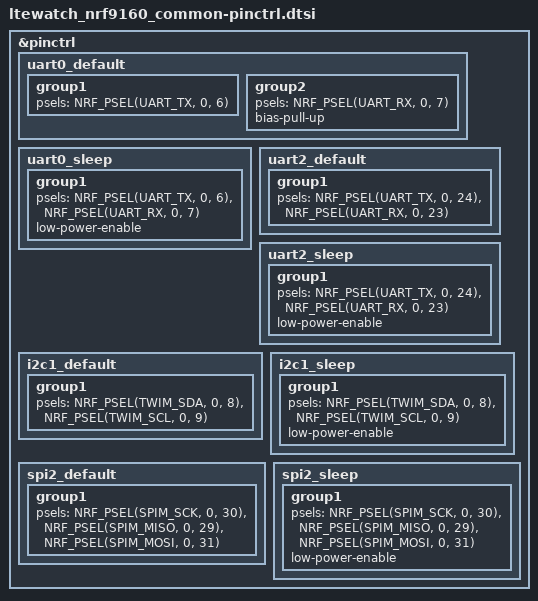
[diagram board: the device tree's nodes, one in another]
/*
 * Copyright (c) 2022 Nordic Semiconductor
 * SPDX-License-Identifier: Apache-2.0
 */

&pinctrl {
	uart0_default: uart0_default {
		group1 {
			psels = <NRF_PSEL(UART_TX, 0, 6)>;
		};
		group2 {
			psels = <NRF_PSEL(UART_RX, 0, 7)>;
			bias-pull-up;
		};
	};

	uart0_sleep: uart0_sleep {
		group1 {
			psels = <NRF_PSEL(UART_TX, 0, 6)>,
				<NRF_PSEL(UART_RX, 0, 7)>;
			low-power-enable;
		};
	};

	uart2_default: uart2_default {
		group1 {
			psels = <NRF_PSEL(UART_TX, 0, 24)>,
				<NRF_PSEL(UART_RX, 0, 23)>;
		};
	};
	
	uart2_sleep: uart2_sleep {
		group1 {
			psels = <NRF_PSEL(UART_TX, 0, 24)>,
				<NRF_PSEL(UART_RX, 0, 23)>;
			low-power-enable;
		};
	};

	i2c1_default: i2c1_default {
		group1 {
			psels = <NRF_PSEL(TWIM_SDA, 0, 8)>,
				<NRF_PSEL(TWIM_SCL, 0, 9)>;
		};
	};

	i2c1_sleep: i2c1_sleep {
		group1 {
			psels = <NRF_PSEL(TWIM_SDA, 0, 8)>,
				<NRF_PSEL(TWIM_SCL, 0, 9)>;
			low-power-enable;
		};
	};

	spi2_default: spi2_default {
		group1 {
			psels = <NRF_PSEL(SPIM_SCK, 0, 30)>,
					<NRF_PSEL(SPIM_MISO, 0, 29)>,
					<NRF_PSEL(SPIM_MOSI, 0, 31)>;
		};
	};

	spi2_sleep: spi2_sleep {
		group1 {
			psels = <NRF_PSEL(SPIM_SCK, 0, 30)>,
					<NRF_PSEL(SPIM_MISO, 0, 29)>,
					<NRF_PSEL(SPIM_MOSI, 0, 31)>;
			low-power-enable;
		};
	};
};
